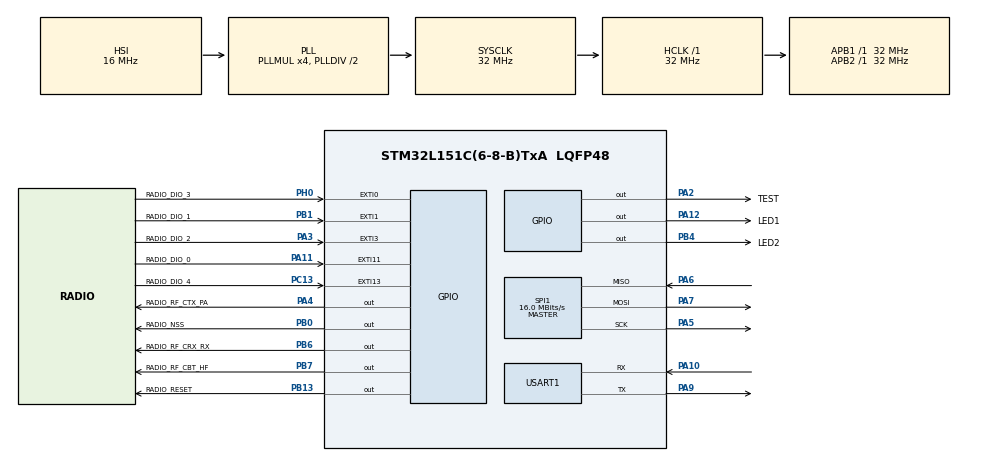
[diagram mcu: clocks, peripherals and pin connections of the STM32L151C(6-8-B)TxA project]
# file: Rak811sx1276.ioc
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Mcu.Family=STM32L1
Mcu.Name=STM32L151C(6-8-B)TxA
Mcu.Package=LQFP48
NVIC.EXTI0_IRQn=true\:0\:0\:false\:false\:true\:true
NVIC.EXTI15_10_IRQn=true\:0\:0\:false\:false\:true\:true
NVIC.EXTI1_IRQn=true\:0\:0\:false\:false\:true\:true
NVIC.EXTI3_IRQn=true\:0\:0\:false\:false\:true\:true
NVIC.PriorityGroup=NVIC_PRIORITYGROUP_4
PA10.Mode=Asynchronous
PA10.Signal=USART1_RX
PA11.GPIO_Label=RADIO_DIO_0
PA11.GPIO_PuPd=GPIO_PULLUP
PA11.Signal=GPXTI11
PA12.GPIO_Label=LED1
PA12.PinState=GPIO_PIN_SET
PA12.Signal=GPIO_Output
PA13.Mode=Serial_Wire
PA13.Signal=SYS_JTMS-SWDIO
PA14.Mode=Serial_Wire
PA14.Signal=SYS_JTCK-SWCLK
PA2.GPIO_Label=TEST
PA2.GPIO_ModeDefaultOutputPP=GPIO_MODE_OUTPUT_OD
PA2.GPIO_PuPd=GPIO_NOPULL
PA2.Signal=GPIO_Output
PA3.GPIO_Label=RADIO_DIO_2
PA3.GPIO_PuPd=GPIO_PULLUP
PA3.Signal=GPXTI3
PA4.GPIO_Label=RADIO_RF_CTX_PA
PA4.GPIO_PuPd=GPIO_PULLUP
PA4.GPIO_Speed=GPIO_SPEED_FREQ_VERY_HIGH
PA4.Signal=GPIO_Output
PA5.Mode=Full_Duplex_Master
PA5.Signal=SPI1_SCK
PA6.Mode=Full_Duplex_Master
PA6.Signal=SPI1_MISO
PA7.Mode=Full_Duplex_Master
PA7.Signal=SPI1_MOSI
PA9.Mode=Asynchronous
PA9.Signal=USART1_TX
PB0.GPIO_Label=RADIO_NSS
PB0.GPIO_PuPd=GPIO_PULLUP
PB0.GPIO_Speed=GPIO_SPEED_FREQ_VERY_HIGH
PB0.PinState=GPIO_PIN_SET
PB0.Signal=GPIO_Output
PB1.GPIO_Label=RADIO_DIO_1
PB1.GPIO_PuPd=GPIO_PULLUP
PB1.Signal=GPXTI1
PB13.GPIO_Label=RADIO_RESET
PB13.PinState=GPIO_PIN_SET
PB13.Signal=GPIO_Output
PB4.GPIO_Label=LED2
PB4.PinState=GPIO_PIN_SET
PB4.Signal=GPIO_Output
PB6.GPIO_Label=RADIO_RF_CRX_RX
PB6.GPIO_PuPd=GPIO_PULLUP
PB6.GPIO_Speed=GPIO_SPEED_FREQ_VERY_HIGH
PB6.Signal=GPIO_Output
PB7.GPIO_Label=RADIO_RF_CBT_HF
PB7.GPIO_PuPd=GPIO_PULLUP
PB7.GPIO_Speed=GPIO_SPEED_FREQ_VERY_HIGH
PB7.Signal=GPIO_Output
PC13-WKUP2.GPIO_Label=RADIO_DIO_4
PC13-WKUP2.GPIO_PuPd=GPIO_PULLUP
PC13-WKUP2.Signal=GPXTI13
PC14-OSC32_IN.Mode=LSE-External-Oscillator
PC14-OSC32_IN.Signal=RCC_OSC32_IN
PC15-OSC32_OUT.Mode=LSE-External-Oscillator
PC15-OSC32_OUT.Signal=RCC_OSC32_OUT
PH0-OSC_IN.GPIO_Label=RADIO_DIO_3
PH0-OSC_IN.GPIO_PuPd=GPIO_PULLUP
PH0-OSC_IN.Signal=GPXTI0
PH1-OSC_OUT.Signal=RCC_OSC_OUT
ProjectManager.HeapSize=0x200
ProjectManager.StackSize=0x400
ProjectManager.TargetToolchain=SW4STM32
RCC.48MHZClocksFreq_Value=32000000
RCC.AHBFreq_Value=32000000
RCC.APB1Freq_Value=32000000
RCC.APB1TimFreq_Value=32000000
RCC.APB2Freq_Value=32000000
RCC.APB2TimFreq_Value=32000000
RCC.HCLKFreq_Value=32000000
RCC.HSE_VALUE=24000000
RCC.HSI_VALUE=16000000
RCC.MSI_VALUE=2097000
RCC.PLLMUL=RCC_PLL_MUL4
RCC.SYSCLKFreq_VALUE=32000000
RCC.SYSCLKSource=RCC_SYSCLKSOURCE_PLLCLK
RCC.VCOOutputFreq_Value=64000000
SPI1.CalculateBaudRate=16.0 MBits/s
SPI1.Direction=SPI_DIRECTION_2LINES
SPI1.Mode=SPI_MODE_MASTER
SPI1.VirtualType=VM_MASTER
USART1.VirtualMode=VM_ASYNC
board=custom

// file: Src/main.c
/**
  ******************************************************************************
  * @file           : main.c
  * @brief          : Main program body
  ******************************************************************************
  ** This notice applies to any and all portions of this file
  * that are not between comment pairs USER CODE BEGIN and
  * USER CODE END. Other portions of this file, whether
  * inserted by the user or by software development tools
  * are owned by their respective copyright owners.
  *
  * COPYRIGHT(c) 2018 STMicroelectronics
  *
  * Redistribution and use in source and binary forms, with or without modification,
  * are permitted provided that the following conditions are met:
  *   1. Redistributions of source code must retain the above copyright notice,
  *      this list of conditions and the following disclaimer.
  *   2. Redistributions in binary form must reproduce the above copyright notice,
  *      this list of conditions and the following disclaimer in the documentation
  *      and/or other materials provided with the distribution.
  *   3. Neither the name of STMicroelectronics nor the names of its contributors
  *      may be used to endorse or promote products derived from this software
  *      without specific prior written permission.
  *
  * THIS SOFTWARE IS PROVIDED BY THE COPYRIGHT HOLDERS AND CONTRIBUTORS "AS IS"
  * AND ANY EXPRESS OR IMPLIED WARRANTIES, INCLUDING, BUT NOT LIMITED TO, THE
  * IMPLIED WARRANTIES OF MERCHANTABILITY AND FITNESS FOR A PARTICULAR PURPOSE ARE
  * DISCLAIMED. IN NO EVENT SHALL THE COPYRIGHT HOLDER OR CONTRIBUTORS BE LIABLE
  * FOR ANY DIRECT, INDIRECT, INCIDENTAL, SPECIAL, EXEMPLARY, OR CONSEQUENTIAL
  * DAMAGES (INCLUDING, BUT NOT LIMITED TO, PROCUREMENT OF SUBSTITUTE GOODS OR
  * SERVICES; LOSS OF USE, DATA, OR PROFITS; OR BUSINESS INTERRUPTION) HOWEVER
  * CAUSED AND ON ANY THEORY OF LIABILITY, WHETHER IN CONTRACT, STRICT LIABILITY,
  * OR TORT (INCLUDING NEGLIGENCE OR OTHERWISE) ARISING IN ANY WAY OUT OF THE USE
  * OF THIS SOFTWARE, EVEN IF ADVISED OF THE POSSIBILITY OF SUCH DAMAGE.
  *
  ******************************************************************************
  */
#include "main.h"
#include "stm32l1xx_hal.h"

/* USER CODE BEGIN Includes */

#include "radio.h"
#include "sx1276.h"
/* USER CODE END Includes */

SPI_HandleTypeDef hspi1;

UART_HandleTypeDef huart1;

/* USER CODE BEGIN PV */
/* Private variables ---------------------------------------------------------*/

/* USER CODE END PV */

void SystemClock_Config(void);
static void MX_GPIO_Init(void);
static void MX_SPI1_Init(void);
static void MX_USART1_UART_Init(void);

/* USER CODE BEGIN PFP */
/* Private function prototypes -----------------------------------------------*/

/* USER CODE END PFP */

int main(void)
{

  /* MCU Configuration----------------------------------------------------------*/

  /* Reset of all peripherals, Initializes the Flash interface and the Systick. */
  HAL_Init();

  /* Configure the system clock */
  SystemClock_Config();

  /* Initialize all configured peripherals */
  MX_GPIO_Init();
  MX_SPI1_Init();
  MX_USART1_UART_Init();
  /* USER CODE BEGIN 2 */
  printf("SX1276 Demo\r\n");
  printf("Sends dummy information to The Things Network\r\n");
  SX1276Init();
  /* USER CODE END 2 */

  /* Infinite loop */
  while (1)
  {

  }

}

void SystemClock_Config(void)
{

  RCC_OscInitTypeDef RCC_OscInitStruct;
  RCC_ClkInitTypeDef RCC_ClkInitStruct;

    /**Configure the main internal regulator output voltage
    */
  __HAL_PWR_VOLTAGESCALING_CONFIG(PWR_REGULATOR_VOLTAGE_SCALE1);

    /**Initializes the CPU, AHB and APB busses clocks
    */
  RCC_OscInitStruct.OscillatorType = RCC_OSCILLATORTYPE_HSI;
  RCC_OscInitStruct.HSIState = RCC_HSI_ON;
  RCC_OscInitStruct.HSICalibrationValue = 16;
  RCC_OscInitStruct.PLL.PLLState = RCC_PLL_ON;
  RCC_OscInitStruct.PLL.PLLSource = RCC_PLLSOURCE_HSI;
  RCC_OscInitStruct.PLL.PLLMUL = RCC_PLL_MUL4;
  RCC_OscInitStruct.PLL.PLLDIV = RCC_PLL_DIV2;
  if (HAL_RCC_OscConfig(&RCC_OscInitStruct) != HAL_OK)
  {
    _Error_Handler(__FILE__, __LINE__);
  }

    /**Initializes the CPU, AHB and APB busses clocks
    */
  RCC_ClkInitStruct.ClockType = RCC_CLOCKTYPE_HCLK|RCC_CLOCKTYPE_SYSCLK
                              |RCC_CLOCKTYPE_PCLK1|RCC_CLOCKTYPE_PCLK2;
  RCC_ClkInitStruct.SYSCLKSource = RCC_SYSCLKSOURCE_PLLCLK;
  RCC_ClkInitStruct.AHBCLKDivider = RCC_SYSCLK_DIV1;
  RCC_ClkInitStruct.APB1CLKDivider = RCC_HCLK_DIV1;
  RCC_ClkInitStruct.APB2CLKDivider = RCC_HCLK_DIV1;

  if (HAL_RCC_ClockConfig(&RCC_ClkInitStruct, FLASH_LATENCY_1) != HAL_OK)
  {
    _Error_Handler(__FILE__, __LINE__);
  }

    /**Configure the Systick interrupt time
    */
  HAL_SYSTICK_Config(HAL_RCC_GetHCLKFreq()/1000);

    /**Configure the Systick
    */
  HAL_SYSTICK_CLKSourceConfig(SYSTICK_CLKSOURCE_HCLK);

  /* SysTick_IRQn interrupt configuration */
  HAL_NVIC_SetPriority(SysTick_IRQn, 0, 0);
}

/* SPI1 init function */
static void MX_SPI1_Init(void)
{

  /* SPI1 parameter configuration*/
  hspi1.Instance = SPI1;
  hspi1.Init.Mode = SPI_MODE_MASTER;
  hspi1.Init.Direction = SPI_DIRECTION_2LINES;
  hspi1.Init.DataSize = SPI_DATASIZE_8BIT;
  hspi1.Init.CLKPolarity = SPI_POLARITY_LOW;
  hspi1.Init.CLKPhase = SPI_PHASE_1EDGE;
  hspi1.Init.NSS = SPI_NSS_SOFT;
  hspi1.Init.BaudRatePrescaler = SPI_BAUDRATEPRESCALER_2;
  hspi1.Init.FirstBit = SPI_FIRSTBIT_MSB;
  hspi1.Init.TIMode = SPI_TIMODE_DISABLE;
  hspi1.Init.CRCCalculation = SPI_CRCCALCULATION_DISABLE;
  hspi1.Init.CRCPolynomial = 10;
  if (HAL_SPI_Init(&hspi1) != HAL_OK)
  {
    _Error_Handler(__FILE__, __LINE__);
  }

}

/* USART1 init function */
static void MX_USART1_UART_Init(void)
{

  huart1.Instance = USART1;
  huart1.Init.BaudRate = 115200;
  huart1.Init.WordLength = UART_WORDLENGTH_8B;
  huart1.Init.StopBits = UART_STOPBITS_1;
  huart1.Init.Parity = UART_PARITY_NONE;
  huart1.Init.Mode = UART_MODE_TX_RX;
  huart1.Init.HwFlowCtl = UART_HWCONTROL_NONE;
  huart1.Init.OverSampling = UART_OVERSAMPLING_16;
  if (HAL_UART_Init(&huart1) != HAL_OK)
  {
    _Error_Handler(__FILE__, __LINE__);
  }

}

/** Configure pins as
        * Analog
        * Input
        * Output
        * EVENT_OUT
        * EXTI
*/
static void MX_GPIO_Init(void)
{

  GPIO_InitTypeDef GPIO_InitStruct;

  /* GPIO Ports Clock Enable */
  __HAL_RCC_GPIOC_CLK_ENABLE();
  __HAL_RCC_GPIOH_CLK_ENABLE();
  __HAL_RCC_GPIOA_CLK_ENABLE();
  __HAL_RCC_GPIOB_CLK_ENABLE();

  /*Configure GPIO pin Output Level */
  HAL_GPIO_WritePin(GPIOA, TEST_Pin|RADIO_RF_CTX_PA_Pin, GPIO_PIN_RESET);

  /*Configure GPIO pin Output Level */
  HAL_GPIO_WritePin(GPIOB, RADIO_NSS_Pin|RADIO_RESET_Pin|LED2_Pin, GPIO_PIN_SET);

  /*Configure GPIO pin Output Level */
  HAL_GPIO_WritePin(LED1_GPIO_Port, LED1_Pin, GPIO_PIN_SET);

  /*Configure GPIO pin Output Level */
  HAL_GPIO_WritePin(GPIOB, RADIO_RF_CRX_RX_Pin|RADIO_RF_CBT_HF_Pin, GPIO_PIN_RESET);

  /*Configure GPIO pin : RADIO_DIO_4_Pin */
  GPIO_InitStruct.Pin = RADIO_DIO_4_Pin;
  GPIO_InitStruct.Mode = GPIO_MODE_IT_RISING;
  GPIO_InitStruct.Pull = GPIO_PULLUP;
  HAL_GPIO_Init(RADIO_DIO_4_GPIO_Port, &GPIO_InitStruct);

  /*Configure GPIO pin : RADIO_DIO_3_Pin */
  GPIO_InitStruct.Pin = RADIO_DIO_3_Pin;
  GPIO_InitStruct.Mode = GPIO_MODE_IT_RISING;
  GPIO_InitStruct.Pull = GPIO_PULLUP;
  HAL_GPIO_Init(RADIO_DIO_3_GPIO_Port, &GPIO_InitStruct);

  /*Configure GPIO pin : TEST_Pin */
  GPIO_InitStruct.Pin = TEST_Pin;
  GPIO_InitStruct.Mode = GPIO_MODE_OUTPUT_OD;
  GPIO_InitStruct.Pull = GPIO_NOPULL;
  GPIO_InitStruct.Speed = GPIO_SPEED_FREQ_LOW;
  HAL_GPIO_Init(TEST_GPIO_Port, &GPIO_InitStruct);

  /*Configure GPIO pins : RADIO_DIO_2_Pin RADIO_DIO_0_Pin */
  GPIO_InitStruct.Pin = RADIO_DIO_2_Pin|RADIO_DIO_0_Pin;
  GPIO_InitStruct.Mode = GPIO_MODE_IT_RISING;
  GPIO_InitStruct.Pull = GPIO_PULLUP;
  HAL_GPIO_Init(GPIOA, &GPIO_InitStruct);

  /*Configure GPIO pin : RADIO_RF_CTX_PA_Pin */
  GPIO_InitStruct.Pin = RADIO_RF_CTX_PA_Pin;
  GPIO_InitStruct.Mode = GPIO_MODE_OUTPUT_PP;
  GPIO_InitStruct.Pull = GPIO_PULLUP;
  GPIO_InitStruct.Speed = GPIO_SPEED_FREQ_VERY_HIGH;
  HAL_GPIO_Init(RADIO_RF_CTX_PA_GPIO_Port, &GPIO_InitStruct);

  /*Configure GPIO pins : RADIO_NSS_Pin RADIO_RF_CRX_RX_Pin RADIO_RF_CBT_HF_Pin */
  GPIO_InitStruct.Pin = RADIO_NSS_Pin|RADIO_RF_CRX_RX_Pin|RADIO_RF_CBT_HF_Pin;
  GPIO_InitStruct.Mode = GPIO_MODE_OUTPUT_PP;
  GPIO_InitStruct.Pull = GPIO_PULLUP;
  GPIO_InitStruct.Speed = GPIO_SPEED_FREQ_VERY_HIGH;
  HAL_GPIO_Init(GPIOB, &GPIO_InitStruct);

  /*Configure GPIO pin : RADIO_DIO_1_Pin */
  GPIO_InitStruct.Pin = RADIO_DIO_1_Pin;
  GPIO_InitStruct.Mode = GPIO_MODE_IT_RISING;
  GPIO_InitStruct.Pull = GPIO_PULLUP;
  HAL_GPIO_Init(RADIO_DIO_1_GPIO_Port, &GPIO_InitStruct);

  /*Configure GPIO pins : RADIO_RESET_Pin LED2_Pin */
  GPIO_InitStruct.Pin = RADIO_RESET_Pin|LED2_Pin;
  GPIO_InitStruct.Mode = GPIO_MODE_OUTPUT_PP;
  GPIO_InitStruct.Pull = GPIO_NOPULL;
  GPIO_InitStruct.Speed = GPIO_SPEED_FREQ_LOW;
  HAL_GPIO_Init(GPIOB, &GPIO_InitStruct);

  /*Configure GPIO pin : LED1_Pin */
  GPIO_InitStruct.Pin = LED1_Pin;
  GPIO_InitStruct.Mode = GPIO_MODE_OUTPUT_PP;
  GPIO_InitStruct.Pull = GPIO_NOPULL;
  GPIO_InitStruct.Speed = GPIO_SPEED_FREQ_LOW;
  HAL_GPIO_Init(LED1_GPIO_Port, &GPIO_InitStruct);

  /* EXTI interrupt init*/
  HAL_NVIC_SetPriority(EXTI0_IRQn, 0, 0);
  HAL_NVIC_EnableIRQ(EXTI0_IRQn);

  HAL_NVIC_SetPriority(EXTI1_IRQn, 0, 0);
  HAL_NVIC_EnableIRQ(EXTI1_IRQn);

  HAL_NVIC_SetPriority(EXTI3_IRQn, 0, 0);
  HAL_NVIC_EnableIRQ(EXTI3_IRQn);

  HAL_NVIC_SetPriority(EXTI15_10_IRQn, 0, 0);
  HAL_NVIC_EnableIRQ(EXTI15_10_IRQn);

}

void _Error_Handler(char *file, int line)
{
  while(1)
  {
  }
}

/************************ (C) COPYRIGHT STMicroelectronics *****END OF FILE****/
